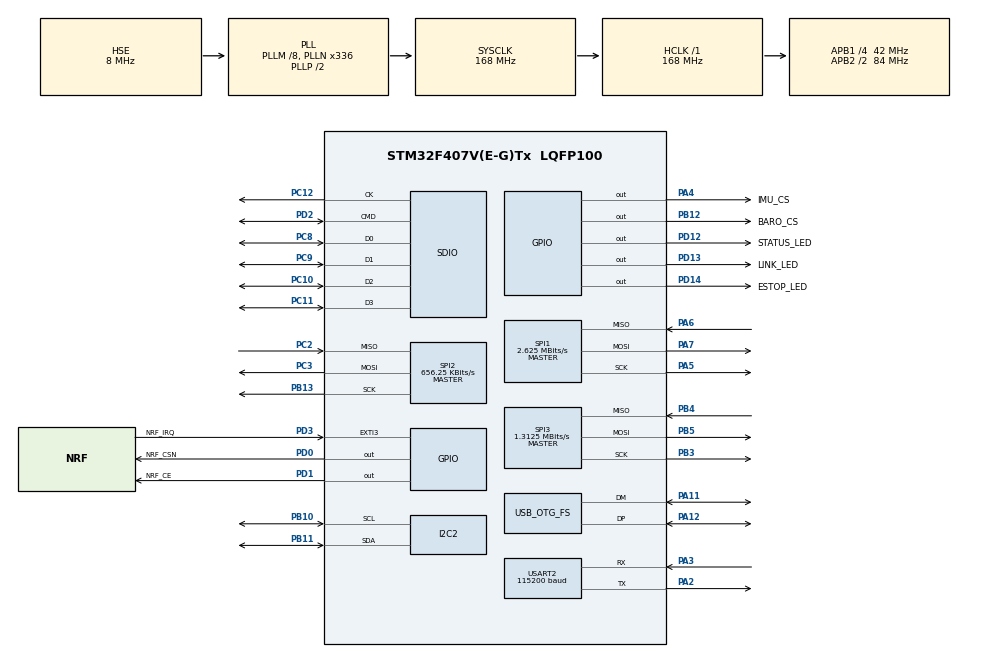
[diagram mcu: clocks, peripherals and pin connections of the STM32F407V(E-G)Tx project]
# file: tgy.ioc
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Dma.I2C2_RX.4.Direction=DMA_PERIPH_TO_MEMORY
Dma.I2C2_RX.4.FIFOMode=DMA_FIFOMODE_DISABLE
Dma.I2C2_RX.4.Instance=DMA1_Stream2
Dma.I2C2_RX.4.MemDataAlignment=DMA_MDATAALIGN_BYTE
Dma.I2C2_RX.4.MemInc=DMA_MINC_ENABLE
Dma.I2C2_RX.4.Mode=DMA_NORMAL
Dma.I2C2_RX.4.PeriphDataAlignment=DMA_PDATAALIGN_BYTE
Dma.I2C2_RX.4.PeriphInc=DMA_PINC_DISABLE
Dma.I2C2_RX.4.Priority=DMA_PRIORITY_MEDIUM
Dma.I2C2_TX.5.Direction=DMA_MEMORY_TO_PERIPH
Dma.I2C2_TX.5.FIFOMode=DMA_FIFOMODE_DISABLE
Dma.I2C2_TX.5.Instance=DMA1_Stream7
Dma.I2C2_TX.5.MemDataAlignment=DMA_MDATAALIGN_BYTE
Dma.I2C2_TX.5.MemInc=DMA_MINC_ENABLE
Dma.I2C2_TX.5.Mode=DMA_NORMAL
Dma.I2C2_TX.5.PeriphDataAlignment=DMA_PDATAALIGN_BYTE
Dma.I2C2_TX.5.PeriphInc=DMA_PINC_DISABLE
Dma.I2C2_TX.5.Priority=DMA_PRIORITY_MEDIUM
Dma.Request0=SPI1_RX
Dma.Request1=SPI1_TX
Dma.Request2=SPI2_RX
Dma.Request3=SPI2_TX
Dma.Request4=I2C2_RX
Dma.Request5=I2C2_TX
Dma.SPI1_RX.0.Direction=DMA_PERIPH_TO_MEMORY
Dma.SPI1_RX.0.FIFOMode=DMA_FIFOMODE_DISABLE
Dma.SPI1_RX.0.Instance=DMA2_Stream0
Dma.SPI1_RX.0.MemDataAlignment=DMA_MDATAALIGN_BYTE
Dma.SPI1_RX.0.MemInc=DMA_MINC_ENABLE
Dma.SPI1_RX.0.Mode=DMA_NORMAL
Dma.SPI1_RX.0.PeriphDataAlignment=DMA_PDATAALIGN_BYTE
Dma.SPI1_RX.0.PeriphInc=DMA_PINC_DISABLE
Dma.SPI1_RX.0.Priority=DMA_PRIORITY_VERY_HIGH
Dma.SPI1_TX.1.Direction=DMA_MEMORY_TO_PERIPH
Dma.SPI1_TX.1.FIFOMode=DMA_FIFOMODE_DISABLE
Dma.SPI1_TX.1.Instance=DMA2_Stream3
Dma.SPI1_TX.1.MemDataAlignment=DMA_MDATAALIGN_BYTE
Dma.SPI1_TX.1.MemInc=DMA_MINC_ENABLE
Dma.SPI1_TX.1.Mode=DMA_NORMAL
Dma.SPI1_TX.1.PeriphDataAlignment=DMA_PDATAALIGN_BYTE
Dma.SPI1_TX.1.PeriphInc=DMA_PINC_DISABLE
Dma.SPI1_TX.1.Priority=DMA_PRIORITY_VERY_HIGH
Dma.SPI2_RX.2.Direction=DMA_PERIPH_TO_MEMORY
Dma.SPI2_RX.2.FIFOMode=DMA_FIFOMODE_DISABLE
Dma.SPI2_RX.2.Instance=DMA1_Stream3
Dma.SPI2_RX.2.MemDataAlignment=DMA_MDATAALIGN_BYTE
Dma.SPI2_RX.2.MemInc=DMA_MINC_ENABLE
Dma.SPI2_RX.2.Mode=DMA_NORMAL
Dma.SPI2_RX.2.PeriphDataAlignment=DMA_PDATAALIGN_BYTE
Dma.SPI2_RX.2.PeriphInc=DMA_PINC_DISABLE
Dma.SPI2_RX.2.Priority=DMA_PRIORITY_HIGH
Dma.SPI2_TX.3.Direction=DMA_MEMORY_TO_PERIPH
Dma.SPI2_TX.3.FIFOMode=DMA_FIFOMODE_DISABLE
Dma.SPI2_TX.3.Instance=DMA1_Stream4
Dma.SPI2_TX.3.MemDataAlignment=DMA_MDATAALIGN_BYTE
Dma.SPI2_TX.3.MemInc=DMA_MINC_ENABLE
Dma.SPI2_TX.3.Mode=DMA_NORMAL
Dma.SPI2_TX.3.PeriphDataAlignment=DMA_PDATAALIGN_BYTE
Dma.SPI2_TX.3.PeriphInc=DMA_PINC_DISABLE
Dma.SPI2_TX.3.Priority=DMA_PRIORITY_HIGH
FATFS._USE_FASTSEEK=0
Mcu.Family=STM32F4
Mcu.Name=STM32F407V(E-G)Tx
Mcu.Package=LQFP100
NVIC.DMA1_Stream2_IRQn=true\:8\:0\:true\:false\:true\:false\:true\:true
NVIC.DMA1_Stream3_IRQn=true\:5\:0\:true\:false\:true\:false\:true\:true
NVIC.DMA1_Stream4_IRQn=true\:5\:0\:true\:false\:true\:false\:true\:true
NVIC.DMA1_Stream7_IRQn=true\:8\:0\:true\:false\:true\:false\:true\:true
NVIC.DMA2_Stream0_IRQn=true\:6\:0\:true\:false\:true\:false\:true\:true
NVIC.DMA2_Stream5_IRQn=true\:6\:0\:false\:false\:true\:false\:true\:true
NVIC.EXTI3_IRQn=true\:6\:0\:true\:false\:true\:true\:true\:true
NVIC.I2C2_ER_IRQn=true\:8\:0\:true\:false\:true\:true\:true\:true
NVIC.I2C2_EV_IRQn=true\:8\:0\:true\:false\:true\:true\:true\:true
NVIC.OTG_FS_IRQn=true\:0\:0\:false\:false\:true\:false\:true\:true
NVIC.PriorityGroup=NVIC_PRIORITYGROUP_4
NVIC.SDIO_IRQn=true\:9\:0\:true\:false\:true\:true\:true\:true
NVIC.SPI1_IRQn=true\:5\:0\:true\:false\:true\:true\:true\:true
NVIC.TIM5_IRQn=true\:7\:0\:true\:false\:true\:true\:true\:true
PA11.Mode=Device_Only
PA11.Signal=USB_OTG_FS_DM
PA12.Mode=Device_Only
PA12.Signal=USB_OTG_FS_DP
PA13.Mode=Serial_Wire
PA13.Signal=SYS_JTMS-SWDIO
PA14.Mode=Serial_Wire
PA14.Signal=SYS_JTCK-SWCLK
PA4.GPIO_Label=IMU_CS
PA4.PinState=GPIO_PIN_SET
PA4.Signal=GPIO_Output
PA5.Mode=Full_Duplex_Master
PA5.Signal=SPI1_SCK
PA6.Mode=Full_Duplex_Master
PA6.Signal=SPI1_MISO
PA7.Mode=Full_Duplex_Master
PA7.Signal=SPI1_MOSI
PB10.Mode=I2C
PB10.Signal=I2C2_SCL
PB11.Mode=I2C
PB11.Signal=I2C2_SDA
PB12.GPIO_Label=BARO_CS
PB12.PinState=GPIO_PIN_SET
PB12.Signal=GPIO_Output
PB13.Mode=Full_Duplex_Master
PB13.Signal=SPI2_SCK
PB3.Mode=Full_Duplex_Master
PB3.Signal=SPI3_SCK
PB4.Mode=Full_Duplex_Master
PB4.Signal=SPI3_MISO
PB5.Mode=Full_Duplex_Master
PB5.Signal=SPI3_MOSI
PC10.Mode=SD_4_bits_Wide_bus
PC10.Signal=SDIO_D2
PC11.Mode=SD_4_bits_Wide_bus
PC11.Signal=SDIO_D3
PC12.Mode=SD_4_bits_Wide_bus
PC12.Signal=SDIO_CK
PC2.Mode=Full_Duplex_Master
PC2.Signal=SPI2_MISO
PC3.Mode=Full_Duplex_Master
PC3.Signal=SPI2_MOSI
PC8.Mode=SD_4_bits_Wide_bus
PC8.Signal=SDIO_D0
PC9.Mode=SD_4_bits_Wide_bus
PC9.Signal=SDIO_D1
PD2.Mode=SD_4_bits_Wide_bus
PD2.Signal=SDIO_CMD
PD0.GPIO_Label=NRF_CSN
PD0.PinState=GPIO_PIN_SET
PD0.Signal=GPIO_Output
PD1.GPIO_Label=NRF_CE
PD1.Signal=GPIO_Output
PD3.GPIO_Label=NRF_IRQ
PD3.GPIO_PuPd=GPIO_PULLUP
PD3.GPIO_ModeDefaultEXTI=GPIO_MODE_IT_FALLING
PD3.Signal=GPXTI3
PD12.GPIO_Label=STATUS_LED
PD12.Signal=GPIO_Output
PD13.GPIO_Label=LINK_LED
PD13.Signal=GPIO_Output
PD14.GPIO_Label=ESTOP_LED
PD14.Signal=GPIO_Output
PH0-OSC_IN.Mode=HSE-External-Oscillator
PH0-OSC_IN.Signal=RCC_OSC_IN
PH1-OSC_OUT.Mode=HSE-External-Oscillator
PH1-OSC_OUT.Signal=RCC_OSC_OUT
ProjectManager.HeapSize=0x200
ProjectManager.StackSize=0x400
ProjectManager.TargetToolchain=STM32CubeIDE
RCC.48MHZClocksFreq_Value=48000000
RCC.AHBFreq_Value=168000000
RCC.APB1CLKDivider=RCC_HCLK_DIV4
RCC.APB1Freq_Value=42000000
RCC.APB1TimFreq_Value=84000000
RCC.APB2CLKDivider=RCC_HCLK_DIV2
RCC.APB2Freq_Value=84000000
RCC.APB2TimFreq_Value=168000000
RCC.CortexFreq_Value=168000000
RCC.HCLKFreq_Value=168000000
RCC.HSE_VALUE=8000000
RCC.HSI_VALUE=16000000
RCC.LSE_VALUE=32768
RCC.PLLM=8
RCC.PLLN=336
RCC.PLLQ=7
RCC.SYSCLKFreq_VALUE=168000000
RCC.SYSCLKSource=RCC_SYSCLKSOURCE_PLLCLK
RCC.VCOOutputFreq_Value=336000000
SDIO.ClockDiv=10
SPI1.BaudRatePrescaler=SPI_BAUDRATEPRESCALER_32
SPI1.CLKPhase=SPI_PHASE_2EDGE
SPI1.CLKPolarity=SPI_POLARITY_HIGH
SPI1.CalculateBaudRate=2.625 MBits/s
SPI1.Direction=SPI_DIRECTION_2LINES
SPI1.Mode=SPI_MODE_MASTER
SPI1.VirtualType=VM_MASTER
SPI2.BaudRatePrescaler=SPI_BAUDRATEPRESCALER_64
SPI2.CalculateBaudRate=656.25 KBits/s
SPI2.Direction=SPI_DIRECTION_2LINES
SPI2.Mode=SPI_MODE_MASTER
SPI2.VirtualType=VM_MASTER
SPI3.BaudRatePrescaler=SPI_BAUDRATEPRESCALER_32
SPI3.CalculateBaudRate=1.3125 MBits/s
SPI3.Direction=SPI_DIRECTION_2LINES
SPI3.Mode=SPI_MODE_MASTER
SPI3.VirtualType=VM_MASTER
TIM2.Prescaler=83
TIM5.Period=\ 4999
TIM5.Prescaler=83
USB_DEVICE.CLASS_NAME_FS=CDC
USB_DEVICE.VirtualMode-CDC_FS=Cdc
USB_DEVICE.VirtualModeFS=Cdc_FS
USB_OTG_FS.VirtualMode=Device_Only
VP_FATFS_VS_SDIO.Mode=SDIO
VP_TIM2_VS_ClockSourceINT.Mode=Internal
VP_TIM5_VS_ClockSourceINT.Mode=Internal
VP_USB_DEVICE_VS_USB_DEVICE_CDC_FS.Mode=CDC_FS
board=STM32F407G-DISC1
Dma.Request6=USART2_TX
Dma.USART2_TX.6.Direction=DMA_MEMORY_TO_PERIPH
Dma.USART2_TX.6.FIFOMode=DMA_FIFOMODE_DISABLE
Dma.USART2_TX.6.Instance=DMA1_Stream6
Dma.USART2_TX.6.MemDataAlignment=DMA_MDATAALIGN_BYTE
Dma.USART2_TX.6.MemInc=DMA_MINC_ENABLE
Dma.USART2_TX.6.Mode=DMA_NORMAL
Dma.USART2_TX.6.PeriphDataAlignment=DMA_PDATAALIGN_BYTE
Dma.USART2_TX.6.PeriphInc=DMA_PINC_DISABLE
Dma.USART2_TX.6.Priority=DMA_PRIORITY_LOW
NVIC.DMA1_Stream6_IRQn=true\:10\:0\:true\:false\:true\:false\:true\:true
PA2.Mode=Asynchronous
PA2.Signal=USART2_TX
PA3.Mode=Asynchronous
PA3.Signal=USART2_RX
USART2.BaudRate=115200
USART2.HwFlowCtl=UART_HWCONTROL_NONE
USART2.Mode=UART_MODE_TX_RX
USART2.OverSampling=UART_OVERSAMPLING_16
USART2.Parity=UART_PARITY_NONE
USART2.StopBits=UART_STOPBITS_1
USART2.VirtualMode-Asynchronous=VM_ASYNC
USART2.WordLength=UART_WORDLENGTH_8B

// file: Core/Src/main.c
/* USER CODE BEGIN Header */
/**
  ******************************************************************************
  * @file           : main.c
  * @brief          : Main program body
  ******************************************************************************
  */
/* USER CODE END Header */
#include "main.h"
#include "dma.h"
#include "fatfs.h"
#include "i2c.h"
#include "sdio.h"
#include "spi.h"
#include "tim.h"
#include "usart.h"
#include "usb_device.h"
#include "gpio.h"

/* USER CODE BEGIN Includes */

#include "app.h"

#include <stdint.h>

/* USER CODE END Includes */

/* USER CODE BEGIN PV */

volatile uint32_t main_loop_heartbeat = 0UL;

/* USER CODE END PV */

void SystemClock_Config(void);

int main(void)
{

  /* MCU Configuration--------------------------------------------------------*/

  /* Reset of all peripherals, Initializes the Flash interface and the Systick. */
  HAL_Init();

  /* Configure the system clock */
  SystemClock_Config();

  /* Initialize all configured peripherals */
  MX_GPIO_Init();
  MX_DMA_Init();
  MX_SPI1_Init();
  MX_SPI2_Init();
  MX_SPI3_Init();
  MX_I2C2_Init();
  MX_TIM2_Init();
  MX_TIM5_Init();
  MX_USART2_UART_Init();
  MX_SDIO_SD_Init();
  MX_FATFS_Init();
  /* USER CODE BEGIN 2 */

  App_Init();

  /* USER CODE END 2 */

  /* Infinite loop */
  /* USER CODE BEGIN WHILE */
  while (1)
  {
    main_loop_heartbeat++;

    App_Run();

    /* USER CODE END WHILE */

  }
}

void SystemClock_Config(void)
{
  RCC_OscInitTypeDef RCC_OscInitStruct = {0};
  RCC_ClkInitTypeDef RCC_ClkInitStruct = {0};

  /** Configure the main internal regulator output voltage
  */
  __HAL_RCC_PWR_CLK_ENABLE();
  __HAL_PWR_VOLTAGESCALING_CONFIG(PWR_REGULATOR_VOLTAGE_SCALE1);

  /** Initializes the RCC Oscillators according to the specified parameters
  * in the RCC_OscInitTypeDef structure.
  */
  RCC_OscInitStruct.OscillatorType = RCC_OSCILLATORTYPE_HSE;
  RCC_OscInitStruct.HSEState = RCC_HSE_ON;
  RCC_OscInitStruct.PLL.PLLState = RCC_PLL_ON;
  RCC_OscInitStruct.PLL.PLLSource = RCC_PLLSOURCE_HSE;
  RCC_OscInitStruct.PLL.PLLM = 8;
  RCC_OscInitStruct.PLL.PLLN = 336;
  RCC_OscInitStruct.PLL.PLLP = RCC_PLLP_DIV2;
  RCC_OscInitStruct.PLL.PLLQ = 7;
  if (HAL_RCC_OscConfig(&RCC_OscInitStruct) != HAL_OK)
  {
    Error_Handler();
  }

  /** Initializes the CPU, AHB and APB buses clocks
  */
  RCC_ClkInitStruct.ClockType = RCC_CLOCKTYPE_HCLK|RCC_CLOCKTYPE_SYSCLK
                              |RCC_CLOCKTYPE_PCLK1|RCC_CLOCKTYPE_PCLK2;
  RCC_ClkInitStruct.SYSCLKSource = RCC_SYSCLKSOURCE_PLLCLK;
  RCC_ClkInitStruct.AHBCLKDivider = RCC_SYSCLK_DIV1;
  RCC_ClkInitStruct.APB1CLKDivider = RCC_HCLK_DIV4;
  RCC_ClkInitStruct.APB2CLKDivider = RCC_HCLK_DIV2;

  if (HAL_RCC_ClockConfig(&RCC_ClkInitStruct, FLASH_LATENCY_5) != HAL_OK)
  {
    Error_Handler();
  }
}

void Error_Handler(void)
{
  __disable_irq();
  while (1)
  {
  }
}

#ifdef  USE_FULL_ASSERT
/**
  * @brief  Reports the name of the source file and the source line number
  *         where the assert_param error has occurred.
  * @param  file: pointer to the source file name
  * @param  line: assert_param error line source number
  * @retval None
  */
void assert_failed(uint8_t *file, uint32_t line)
{
  /* USER CODE BEGIN 6 */

  (void)file;
  (void)line;

  /* USER CODE END 6 */
}
#endif /* USE_FULL_ASSERT */
